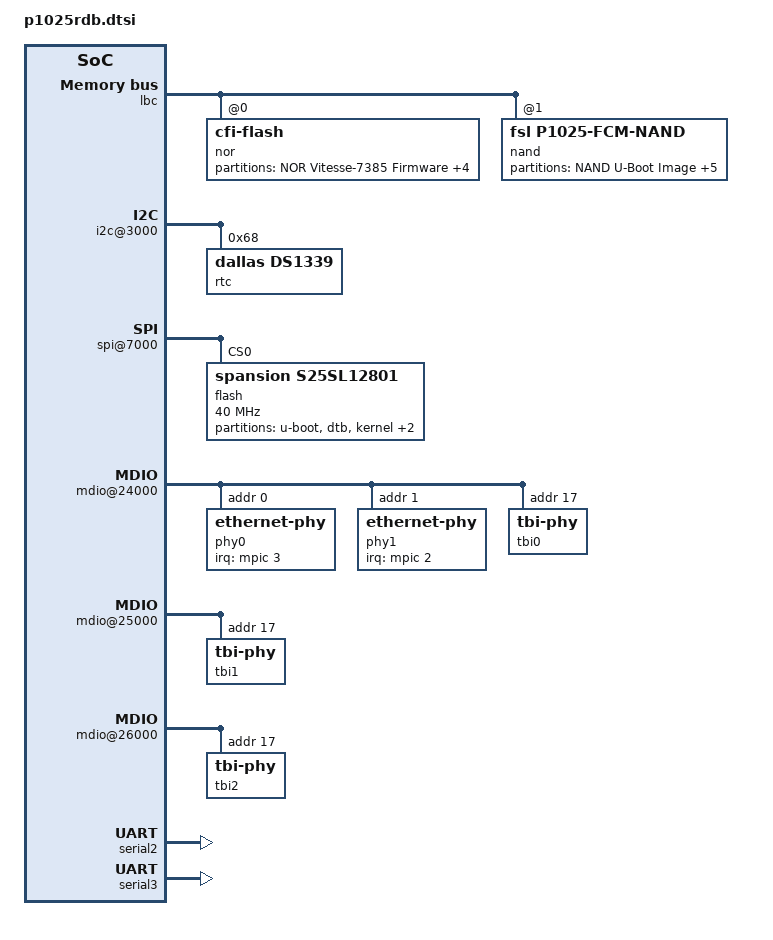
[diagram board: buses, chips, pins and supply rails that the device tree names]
&lbc {
	nor@0,0 {
		#address-cells = <1>;
		#size-cells = <1>;
		compatible = "cfi-flash";
		reg = <0x0 0x0 0x1000000>;
		bank-width = <2>;
		device-width = <1>;
		partition@0 {
			reg = <0x0 0x00040000>;
			label = "NOR Vitesse-7385 Firmware";
			read-only;
		};
		partition@40000 {
			reg = <0x00040000 0x00040000>;
			label = "NOR DTB Image";
		};
		partition@80000 {
			reg = <0x00080000 0x00380000>;
			label = "NOR Linux Kernel Image";
		};
		partition@400000 {
			reg = <0x00400000 0x00b00000>;
			label = "NOR JFFS2 Root File System";
		};
		partition@f00000 {
			reg = <0x00f00000 0x00100000>;
			label = "NOR U-Boot Image";
			read-only;
		};
	};
	nand@1,0 {
		#address-cells = <1>;
		#size-cells = <1>;
		compatible = "fsl,p1025-fcm-nand",
			     "fsl,elbc-fcm-nand";
		reg = <0x1 0x0 0x40000>;
		partition@0 {
			reg = <0x0 0x00100000>;
			label = "NAND U-Boot Image";
			read-only;
		};
		partition@100000 {
			reg = <0x00100000 0x00100000>;
			label = "NAND DTB Image";
		};
		partition@200000 {
			reg = <0x00200000 0x00400000>;
			label = "NAND Linux Kernel Image";
		};
		partition@600000 {
			reg = <0x00600000 0x00400000>;
			label = "NAND Compressed RFS Image";
		};
		partition@a00000 {
			reg = <0x00a00000 0x00700000>;
			label = "NAND JFFS2 Root File System";
		};
		partition@1100000 {
			reg = <0x01100000 0x00f00000>;
			label = "NAND Writable User area";
		};
	};
};
&soc {
	i2c@3000 {
		rtc@68 {
			compatible = "dallas,ds1339";
			reg = <0x68>;
		};
	};
	spi@7000 {
		flash@0 {
			#address-cells = <1>;
			#size-cells = <1>;
			compatible = "spansion,s25sl12801", "jedec,spi-nor";
			reg = <0>;
			spi-max-frequency = <40000000>;  
			partition@u-boot {
				reg = <0x0 0x00080000>;
				label = "u-boot";
				read-only;
			};
			partition@dtb {
				reg = <0x00080000 0x00080000>;
				label = "dtb";
			};
			partition@kernel {
				reg = <0x00100000 0x00400000>;
				label = "kernel";
			};
			partition@fs {
				reg = <0x00500000 0x00400000>;
				label = "file system";
			};
			partition@jffs-fs {
				reg = <0x00900000 0x00700000>;
				label = "file system jffs2";
			};
		};
	};
	usb@22000 {
		phy_type = "ulpi";
	};
	mdio@24000 {
		phy0: ethernet-phy@0 {
			interrupt-parent = <&mpic>;
			interrupts = <3 1>;
			reg = <0x0>;
		};
		phy1: ethernet-phy@1 {
			interrupt-parent = <&mpic>;
			interrupts = <2 1>;
			reg = <0x1>;
		};
		tbi0: tbi-phy@11 {
			reg = <0x11>;
			device_type = "tbi-phy";
		};
	};
	mdio@25000 {
		tbi1: tbi-phy@11 {
			reg = <0x11>;
			device_type = "tbi-phy";
		};
	};
	mdio@26000 {
		tbi2: tbi-phy@11 {
			reg = <0x11>;
			device_type = "tbi-phy";
		};
	};
	enet0: ethernet@b0000 {
		fixed-link = <1 1 1000 0 0>;
		phy-connection-type = "rgmii-id";
	};
	enet1: ethernet@b1000 {
		phy-handle = <&phy0>;
		tbi-handle = <&tbi1>;
		phy-connection-type = "sgmii";
	};
	enet2: ethernet@b2000 {
		phy-handle = <&phy1>;
		phy-connection-type = "rgmii-id";
	};
	par_io@e0100 {
		#address-cells = <1>;
		#size-cells = <1>;
		reg = <0xe0100 0x60>;
		ranges = <0x0 0xe0100 0x60>;
		device_type = "par_io";
		num-ports = <3>;
		pio1: ucc_pin@1 {
			pio-map = <
				0x1  0x13 0x1  0x0  0x1  0x0     
				0x1  0x14 0x3  0x0  0x1  0x0     
				0x0  0x17 0x2  0x0  0x2  0x0     
				0x0  0x18 0x2  0x0  0x1  0x0     
				0x0  0x7  0x1  0x0  0x2  0x0     
				0x0  0x9  0x1  0x0  0x2  0x0     
				0x0  0xb  0x1  0x0  0x2  0x0     
				0x0  0xc  0x1  0x0  0x2  0x0     
				0x0  0x6  0x2  0x0  0x2  0x0     
				0x0  0xa  0x2  0x0  0x2  0x0     
				0x0  0xe  0x2  0x0  0x2  0x0     
				0x0  0xf  0x2  0x0  0x2  0x0     
				0x0  0x5  0x1  0x0  0x2  0x0     
				0x0  0xd  0x1  0x0  0x2  0x0     
				0x0  0x4  0x2  0x0  0x2  0x0     
				0x0  0x8  0x2  0x0  0x2  0x0     
				0x0  0x11 0x2  0x0  0x2  0x0     
				0x0  0x10 0x2  0x0  0x2  0x0>;     
		};
		pio2: ucc_pin@2 {
			pio-map = <
				0x1  0x13 0x1  0x0  0x1  0x0     
				0x1  0x14 0x3  0x0  0x1  0x0     
				0x1  0xb  0x2  0x0  0x1  0x0     
				0x1  0x7  0x1  0x0  0x2  0x0     
				0x1  0xa  0x1  0x0  0x2  0x0     
				0x1  0x6  0x2  0x0  0x2  0x0     
				0x1  0x9  0x2  0x0  0x2  0x0     
				0x1  0x5  0x1  0x0  0x2  0x0     
				0x1  0x4  0x2  0x0  0x2  0x0     
				0x1  0x8  0x2  0x0  0x2  0x0>;     
		};
		pio3: ucc_pin@3 {
			pio-map = <
				0x0  0x16 0x2  0x0  0x2  0x0     
				0x0  0x12 0x2  0x0  0x2  0x0     
				0x0  0x13 0x1  0x0  0x2  0x0     
				0x0  0x14 0x2  0x0  0x2  0x0     
				0x0  0x15 0x1  0x0  0x2  0x0>;     
		};
		pio4: ucc_pin@4 {
			pio-map = <
				0x1  0x0  0x2  0x0  0x2  0x0     
				0x0  0x1c 0x2  0x0  0x2  0x0     
				0x0  0x1d 0x1  0x0  0x2  0x0     
				0x0  0x1e 0x2  0x0  0x2  0x0     
				0x0  0x1f 0x1  0x0  0x2  0x0>;     
		};
	};
};
&qe {
	serial2: ucc@2600 {
		device_type = "serial";
		compatible = "ucc_uart";
		port-number = <0>;
		rx-clock-name = "brg6";
		tx-clock-name = "brg6";
		pio-handle = <&pio3>;
	};
	serial3: ucc@2200 {
		device_type = "serial";
		compatible = "ucc_uart";
		port-number = <1>;
		rx-clock-name = "brg2";
		tx-clock-name = "brg2";
		pio-handle = <&pio4>;
	};
};
